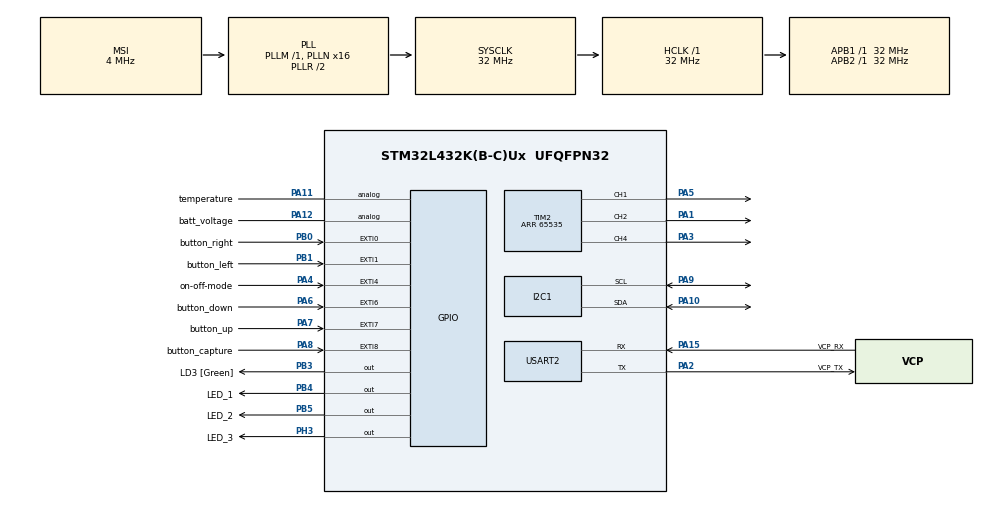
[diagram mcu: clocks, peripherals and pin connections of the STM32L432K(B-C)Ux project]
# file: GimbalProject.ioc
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FREERTOS.BinarySemaphores01=spatialSmphr,Dynamic,NULL;targetSmphr,Dynamic,NULL
FREERTOS.Tasks01=controlSysTask,8,128,StartCtrlSysTask,Default,NULL,Static,controlSysTaskBuffer,controlSysTaskControlBlock;ledBattTask,9,128,StartLedBattTask,Default,NULL,Static,ledBattTaskBuffer,ledBattTaskControlBlock;imuTask,10,128,StartIMUTask,Default,NULL,Static,imuTaskBuffer,imuTaskControlBlock;targetSetTask,12,128,StartTargetSetTask,Default,NULL,Static,targetSetTaskBuffer,targetSetTaskControlBlock;stateTask,13,128,StartStateMachine,Default,NULL,Static,stateTaskBuffer,stateTaskControlBlock;uniqueMovement,8,128,StartUniqueMovement,Default,NULL,Static,uniqueMovementBuffer,uniqueMovementControlBlock
I2C1.Timing=0x00707CBB
Mcu.Family=STM32L4
Mcu.Name=STM32L432K(B-C)Ux
Mcu.Package=UFQFPN32
NVIC.EXTI0_IRQn=true\:5\:0\:false\:false\:true\:true\:true\:true
NVIC.EXTI1_IRQn=true\:5\:0\:false\:false\:true\:true\:true\:true
NVIC.EXTI4_IRQn=true\:5\:0\:false\:false\:true\:true\:true\:true
NVIC.EXTI9_5_IRQn=true\:5\:0\:false\:false\:true\:true\:true\:true
NVIC.PriorityGroup=NVIC_PRIORITYGROUP_4
NVIC.TIM6_DAC_IRQn=true\:15\:0\:false\:false\:true\:false\:false\:true
NVIC.TimeBase=TIM6_DAC_IRQn
NVIC.TimeBaseIP=TIM6
PA0.GPIO_Label=MCO [High speed clock in]
PA0.Mode=HSE-External-Clock-Source-for-LittleOrca
PA0.Signal=RCC_CK_IN
PA1.Signal=S_TIM2_CH2
PA10.Mode=I2C
PA10.Signal=I2C1_SDA
PA11.GPIO_Label=temperature
PA11.Signal=GPIO_Analog
PA12.GPIO_Label=batt_voltage
PA12.Signal=GPIO_Analog
PA13\ (JTMS-SWDIO).GPIO_Label=SWDIO
PA13\ (JTMS-SWDIO).Mode=Serial_Wire
PA13\ (JTMS-SWDIO).Signal=SYS_JTMS-SWDIO
PA14\ (JTCK-SWCLK).GPIO_Label=SWCLK
PA14\ (JTCK-SWCLK).Mode=Serial_Wire
PA14\ (JTCK-SWCLK).Signal=SYS_JTCK-SWCLK
PA15\ (JTDI).GPIO_Label=VCP_RX
PA15\ (JTDI).Mode=Asynchronous
PA15\ (JTDI).Signal=USART2_RX
PA2.GPIO_Label=VCP_TX
PA2.Mode=Asynchronous
PA2.Signal=USART2_TX
PA3.Signal=S_TIM2_CH4
PA4.GPIO_Label=on-off-mode
PA4.GPIO_ModeDefaultEXTI=GPIO_MODE_IT_FALLING
PA4.GPIO_PuPd=GPIO_PULLUP
PA4.Signal=GPXTI4
PA5.Signal=S_TIM2_CH1
PA6.GPIO_Label=button_down
PA6.GPIO_ModeDefaultEXTI=GPIO_MODE_IT_FALLING
PA6.GPIO_PuPd=GPIO_PULLUP
PA6.Signal=GPXTI6
PA7.GPIO_Label=button_up
PA7.GPIO_ModeDefaultEXTI=GPIO_MODE_IT_FALLING
PA7.GPIO_PuPd=GPIO_PULLUP
PA7.Signal=GPXTI7
PA8.GPIO_Label=button_capture
PA8.Signal=GPXTI8
PA9.Mode=I2C
PA9.Signal=I2C1_SCL
PB0.GPIO_Label=button_right
PB0.GPIO_ModeDefaultEXTI=GPIO_MODE_IT_FALLING
PB0.GPIO_PuPd=GPIO_PULLUP
PB0.Signal=GPXTI0
PB1.GPIO_Label=button_left
PB1.GPIO_ModeDefaultEXTI=GPIO_MODE_IT_FALLING
PB1.GPIO_PuPd=GPIO_PULLUP
PB1.Signal=GPXTI1
PB3\ (JTDO-TRACESWO).GPIO_Label=LD3 [Green]
PB3\ (JTDO-TRACESWO).Signal=GPIO_Output
PB4\ (NJTRST).GPIO_Label=LED_1
PB4\ (NJTRST).Signal=GPIO_Output
PB5.GPIO_Label=LED_2
PB5.Signal=GPIO_Output
PB6.Signal=USART1_TX
PB7.Signal=USART1_RX
PC14-OSC32_IN\ (PC14).Mode=LSE-External-Oscillator
PC14-OSC32_IN\ (PC14).Signal=RCC_OSC32_IN
PC15-OSC32_OUT\ (PC15).Mode=LSE-External-Oscillator
PC15-OSC32_OUT\ (PC15).Signal=RCC_OSC32_OUT
PH3-BOOT0.GPIO_Label=LED_3
PH3-BOOT0.Signal=GPIO_Output
ProjectManager.HeapSize=0x200
ProjectManager.StackSize=0x400
ProjectManager.TargetToolchain=STM32CubeIDE
RCC.AHBFreq_Value=32000000
RCC.APB1Freq_Value=32000000
RCC.APB1TimFreq_Value=32000000
RCC.APB2Freq_Value=32000000
RCC.APB2TimFreq_Value=32000000
RCC.CortexFreq_Value=32000000
RCC.HCLKFreq_Value=32000000
RCC.HSE_VALUE=8000000
RCC.HSI16_VALUE=16000000
RCC.HSI48_VALUE=48000000
RCC.HSI_VALUE=16000000
RCC.MSI_VALUE=4000000
RCC.PLLMUL=RCC_PLLMUL_4
RCC.PLLN=16
RCC.SYSCLKFreq_VALUE=32000000
RCC.SYSCLKSource=RCC_SYSCLKSOURCE_PLLCLK
RCC.VCOOutputFreq_Value=64000000
SH.S_TIM2_CH1.0=TIM2_CH1,PWM Generation1 CH1
SH.S_TIM2_CH2.0=TIM2_CH2,PWM Generation2 CH2
SH.S_TIM2_CH4.0=TIM2_CH4,PWM Generation4 CH4
TIM2.AutoReloadPreload=TIM_AUTORELOAD_PRELOAD_ENABLE
TIM2.Channel-PWM\ Generation1\ CH1=TIM_CHANNEL_1
TIM2.Channel-PWM\ Generation2\ CH2=TIM_CHANNEL_2
TIM2.Channel-PWM\ Generation4\ CH4=TIM_CHANNEL_4
TIM2.Period=65535
USART2.VirtualMode-Asynchronous=VM_ASYNC
VP_FREERTOS_VS_CMSIS_V2.Mode=CMSIS_V2
VP_SYS_VS_tim6.Mode=TIM6
VP_TIM2_VS_ClockSourceINT.Mode=Internal
board=NUCLEO-L432KC

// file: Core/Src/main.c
/* USER CODE BEGIN Header */
/**
  ******************************************************************************
  * @file           : main.c
  * @brief          : Main program body
  ******************************************************************************
  * @attention
  *
  * <h2><center>&copy; Copyright (c) 2021 STMicroelectronics.
  * All rights reserved.</center></h2>
  *
  * This software component is licensed by ST under BSD 3-Clause license,
  * the "License"; You may not use this file except in compliance with the
  * License. You may obtain a copy of the License at:
  *                        opensource.org/licenses/BSD-3-Clause
  *
  ******************************************************************************
  */
/* USER CODE END Header */
#include "main.h"
#include "cmsis_os.h"

/* USER CODE BEGIN Includes */
#include <stdio.h>
#include "bno055_stm32.h"
/* USER CODE END Includes */

/* USER CODE BEGIN PTD */
#ifdef __GNUC__
  /* With GCC, small printf (option LD Linker->Libraries->Small printf
     set to 'Yes') calls __io_putchar() */
  #define PUTCHAR_PROTOTYPE int __io_putchar(int ch)
#else
  #define PUTCHAR_PROTOTYPE int fputc(int ch, FILE *f)
#endif /* __GNUC__ */
/* USER CODE END PTD */

I2C_HandleTypeDef hi2c1;

TIM_HandleTypeDef htim2;

UART_HandleTypeDef huart2;

/* Definitions for controlSysTask */
osThreadId_t controlSysTaskHandle;
const osThreadAttr_t controlSysTask_attributes = {
  .name = "controlSysTask",
  .stack_size = 128 * 4,
  .priority = (osPriority_t) osPriorityLow,
};
/* Definitions for ledBattTask */
osThreadId_t ledBattTaskHandle;
const osThreadAttr_t ledBattTask_attributes = {
  .name = "ledBattTask",
  .stack_size = 128 * 4,
  .priority = (osPriority_t) osPriorityLow1,
};
/* Definitions for imuTask */
osThreadId_t imuTaskHandle;
const osThreadAttr_t imuTask_attributes = {
  .name = "imuTask",
  .stack_size = 128 * 4,
  .priority = (osPriority_t) osPriorityLow2,
};
/* Definitions for spatialSmphr */
osSemaphoreId_t spatialSmphrHandle;
const osSemaphoreAttr_t spatialSmphr_attributes = {
  .name = "spatialSmphr"
};

void SystemClock_Config(void);
static void MX_GPIO_Init(void);
static void MX_USART2_UART_Init(void);
static void MX_TIM2_Init(void);
static void MX_I2C1_Init(void);
void StartCtrlSysTask(void *argument);
void StartLedBattTask(void *argument);
void StartIMUTask(void *argument);

/* USER CODE BEGIN 0 */
PUTCHAR_PROTOTYPE
{
  /* Place your implementation of fputc here */
  /* e.g. write a character to the EVAL_COM1 and Loop until the end of transmission */
  HAL_UART_Transmit(&huart2, (uint8_t *)&ch, 1, 0xFFFF);

  return ch;
}

bno055_vector_t spatialOrientation;
/* USER CODE END 0 */

int main(void)
{

  /* MCU Configuration--------------------------------------------------------*/

  /* Reset of all peripherals, Initializes the Flash interface and the Systick. */
  HAL_Init();

  /* Configure the system clock */
  SystemClock_Config();

  /* Initialize all configured peripherals */
  MX_GPIO_Init();
  MX_USART2_UART_Init();
  MX_TIM2_Init();
  MX_I2C1_Init();

  /* Init scheduler */
  osKernelInitialize();

  /* Create the semaphores(s) */
  /* creation of spatialSmphr */
  spatialSmphrHandle = osSemaphoreNew(1, 1, &spatialSmphr_attributes);

  /* Create the thread(s) */
  /* creation of controlSysTask */
  controlSysTaskHandle = osThreadNew(StartCtrlSysTask, NULL, &controlSysTask_attributes);

  /* creation of ledBattTask */
  ledBattTaskHandle = osThreadNew(StartLedBattTask, NULL, &ledBattTask_attributes);

  /* creation of imuTask */
  imuTaskHandle = osThreadNew(StartIMUTask, NULL, &imuTask_attributes);

  /* Start scheduler */
  osKernelStart();

  /* We should never get here as control is now taken by the scheduler */
  /* Infinite loop */
  while (1)
  {

  }
}

void SystemClock_Config(void)
{
  RCC_OscInitTypeDef RCC_OscInitStruct = {0};
  RCC_ClkInitTypeDef RCC_ClkInitStruct = {0};

  /** Configure the main internal regulator output voltage
  */
  if (HAL_PWREx_ControlVoltageScaling(PWR_REGULATOR_VOLTAGE_SCALE1) != HAL_OK)
  {
    Error_Handler();
  }
  /** Configure LSE Drive Capability
  */
  HAL_PWR_EnableBkUpAccess();
  __HAL_RCC_LSEDRIVE_CONFIG(RCC_LSEDRIVE_LOW);
  /** Initializes the RCC Oscillators according to the specified parameters
  * in the RCC_OscInitTypeDef structure.
  */
  RCC_OscInitStruct.OscillatorType = RCC_OSCILLATORTYPE_LSE|RCC_OSCILLATORTYPE_MSI;
  RCC_OscInitStruct.LSEState = RCC_LSE_ON;
  RCC_OscInitStruct.MSIState = RCC_MSI_ON;
  RCC_OscInitStruct.MSICalibrationValue = 0;
  RCC_OscInitStruct.MSIClockRange = RCC_MSIRANGE_6;
  RCC_OscInitStruct.PLL.PLLState = RCC_PLL_ON;
  RCC_OscInitStruct.PLL.PLLSource = RCC_PLLSOURCE_MSI;
  RCC_OscInitStruct.PLL.PLLM = 1;
  RCC_OscInitStruct.PLL.PLLN = 16;
  RCC_OscInitStruct.PLL.PLLP = RCC_PLLP_DIV7;
  RCC_OscInitStruct.PLL.PLLQ = RCC_PLLQ_DIV2;
  RCC_OscInitStruct.PLL.PLLR = RCC_PLLR_DIV2;
  if (HAL_RCC_OscConfig(&RCC_OscInitStruct) != HAL_OK)
  {
    Error_Handler();
  }
  /** Initializes the CPU, AHB and APB buses clocks
  */
  RCC_ClkInitStruct.ClockType = RCC_CLOCKTYPE_HCLK|RCC_CLOCKTYPE_SYSCLK
                              |RCC_CLOCKTYPE_PCLK1|RCC_CLOCKTYPE_PCLK2;
  RCC_ClkInitStruct.SYSCLKSource = RCC_SYSCLKSOURCE_PLLCLK;
  RCC_ClkInitStruct.AHBCLKDivider = RCC_SYSCLK_DIV1;
  RCC_ClkInitStruct.APB1CLKDivider = RCC_HCLK_DIV1;
  RCC_ClkInitStruct.APB2CLKDivider = RCC_HCLK_DIV1;

  if (HAL_RCC_ClockConfig(&RCC_ClkInitStruct, FLASH_LATENCY_1) != HAL_OK)
  {
    Error_Handler();
  }
  /** Enable MSI Auto calibration
  */
  HAL_RCCEx_EnableMSIPLLMode();
}

static void MX_I2C1_Init(void)
{

  hi2c1.Instance = I2C1;
  hi2c1.Init.Timing = 0x00707CBB;
  hi2c1.Init.OwnAddress1 = 0;
  hi2c1.Init.AddressingMode = I2C_ADDRESSINGMODE_7BIT;
  hi2c1.Init.DualAddressMode = I2C_DUALADDRESS_DISABLE;
  hi2c1.Init.OwnAddress2 = 0;
  hi2c1.Init.OwnAddress2Masks = I2C_OA2_NOMASK;
  hi2c1.Init.GeneralCallMode = I2C_GENERALCALL_DISABLE;
  hi2c1.Init.NoStretchMode = I2C_NOSTRETCH_DISABLE;
  if (HAL_I2C_Init(&hi2c1) != HAL_OK)
  {
    Error_Handler();
  }
  /** Configure Analogue filter
  */
  if (HAL_I2CEx_ConfigAnalogFilter(&hi2c1, I2C_ANALOGFILTER_ENABLE) != HAL_OK)
  {
    Error_Handler();
  }
  /** Configure Digital filter
  */
  if (HAL_I2CEx_ConfigDigitalFilter(&hi2c1, 0) != HAL_OK)
  {
    Error_Handler();
  }

}

static void MX_TIM2_Init(void)
{

  TIM_ClockConfigTypeDef sClockSourceConfig = {0};
  TIM_MasterConfigTypeDef sMasterConfig = {0};
  TIM_OC_InitTypeDef sConfigOC = {0};

  htim2.Instance = TIM2;
  htim2.Init.Prescaler = 0;
  htim2.Init.CounterMode = TIM_COUNTERMODE_UP;
  htim2.Init.Period = 65535;
  htim2.Init.ClockDivision = TIM_CLOCKDIVISION_DIV1;
  htim2.Init.AutoReloadPreload = TIM_AUTORELOAD_PRELOAD_ENABLE;
  if (HAL_TIM_Base_Init(&htim2) != HAL_OK)
  {
    Error_Handler();
  }
  sClockSourceConfig.ClockSource = TIM_CLOCKSOURCE_INTERNAL;
  if (HAL_TIM_ConfigClockSource(&htim2, &sClockSourceConfig) != HAL_OK)
  {
    Error_Handler();
  }
  if (HAL_TIM_PWM_Init(&htim2) != HAL_OK)
  {
    Error_Handler();
  }
  sMasterConfig.MasterOutputTrigger = TIM_TRGO_RESET;
  sMasterConfig.MasterSlaveMode = TIM_MASTERSLAVEMODE_DISABLE;
  if (HAL_TIMEx_MasterConfigSynchronization(&htim2, &sMasterConfig) != HAL_OK)
  {
    Error_Handler();
  }
  sConfigOC.OCMode = TIM_OCMODE_PWM1;
  sConfigOC.Pulse = 0;
  sConfigOC.OCPolarity = TIM_OCPOLARITY_HIGH;
  sConfigOC.OCFastMode = TIM_OCFAST_DISABLE;
  if (HAL_TIM_PWM_ConfigChannel(&htim2, &sConfigOC, TIM_CHANNEL_1) != HAL_OK)
  {
    Error_Handler();
  }
  if (HAL_TIM_PWM_ConfigChannel(&htim2, &sConfigOC, TIM_CHANNEL_2) != HAL_OK)
  {
    Error_Handler();
  }
  if (HAL_TIM_PWM_ConfigChannel(&htim2, &sConfigOC, TIM_CHANNEL_4) != HAL_OK)
  {
    Error_Handler();
  }
  HAL_TIM_MspPostInit(&htim2);

}

static void MX_USART2_UART_Init(void)
{

  huart2.Instance = USART2;
  huart2.Init.BaudRate = 115200;
  huart2.Init.WordLength = UART_WORDLENGTH_8B;
  huart2.Init.StopBits = UART_STOPBITS_1;
  huart2.Init.Parity = UART_PARITY_NONE;
  huart2.Init.Mode = UART_MODE_TX_RX;
  huart2.Init.HwFlowCtl = UART_HWCONTROL_NONE;
  huart2.Init.OverSampling = UART_OVERSAMPLING_16;
  huart2.Init.OneBitSampling = UART_ONE_BIT_SAMPLE_DISABLE;
  huart2.AdvancedInit.AdvFeatureInit = UART_ADVFEATURE_NO_INIT;
  if (HAL_UART_Init(&huart2) != HAL_OK)
  {
    Error_Handler();
  }

}

static void MX_GPIO_Init(void)
{
  GPIO_InitTypeDef GPIO_InitStruct = {0};

  /* GPIO Ports Clock Enable */
  __HAL_RCC_GPIOC_CLK_ENABLE();
  __HAL_RCC_GPIOA_CLK_ENABLE();
  __HAL_RCC_GPIOB_CLK_ENABLE();
  __HAL_RCC_GPIOH_CLK_ENABLE();

  /*Configure GPIO pin Output Level */
  HAL_GPIO_WritePin(GPIOB, LD3_Pin|LED_1_Pin|LED_2_Pin, GPIO_PIN_RESET);

  /*Configure GPIO pin Output Level */
  HAL_GPIO_WritePin(LED_3_GPIO_Port, LED_3_Pin, GPIO_PIN_RESET);

  /*Configure GPIO pins : button_on_off_mode_Pin button_down_Pin button_up_Pin button_capture_Pin */
  GPIO_InitStruct.Pin = button_on_off_mode_Pin|button_down_Pin|button_up_Pin|button_capture_Pin;
  GPIO_InitStruct.Mode = GPIO_MODE_INPUT;
  GPIO_InitStruct.Pull = GPIO_NOPULL;
  HAL_GPIO_Init(GPIOA, &GPIO_InitStruct);

  /*Configure GPIO pins : button_right_Pin button_left_Pin */
  GPIO_InitStruct.Pin = button_right_Pin|button_left_Pin;
  GPIO_InitStruct.Mode = GPIO_MODE_INPUT;
  GPIO_InitStruct.Pull = GPIO_NOPULL;
  HAL_GPIO_Init(GPIOB, &GPIO_InitStruct);

  /*Configure GPIO pins : temperature_Pin batt_voltage_Pin */
  GPIO_InitStruct.Pin = temperature_Pin|batt_voltage_Pin;
  GPIO_InitStruct.Mode = GPIO_MODE_ANALOG;
  GPIO_InitStruct.Pull = GPIO_NOPULL;
  HAL_GPIO_Init(GPIOA, &GPIO_InitStruct);

  /*Configure GPIO pins : LD3_Pin LED_1_Pin LED_2_Pin */
  GPIO_InitStruct.Pin = LD3_Pin|LED_1_Pin|LED_2_Pin;
  GPIO_InitStruct.Mode = GPIO_MODE_OUTPUT_PP;
  GPIO_InitStruct.Pull = GPIO_NOPULL;
  GPIO_InitStruct.Speed = GPIO_SPEED_FREQ_LOW;
  HAL_GPIO_Init(GPIOB, &GPIO_InitStruct);

  /*Configure GPIO pins : PB6 PB7 */
  GPIO_InitStruct.Pin = GPIO_PIN_6|GPIO_PIN_7;
  GPIO_InitStruct.Mode = GPIO_MODE_AF_PP;
  GPIO_InitStruct.Pull = GPIO_NOPULL;
  GPIO_InitStruct.Speed = GPIO_SPEED_FREQ_VERY_HIGH;
  GPIO_InitStruct.Alternate = GPIO_AF7_USART1;
  HAL_GPIO_Init(GPIOB, &GPIO_InitStruct);

  /*Configure GPIO pin : LED_3_Pin */
  GPIO_InitStruct.Pin = LED_3_Pin;
  GPIO_InitStruct.Mode = GPIO_MODE_OUTPUT_PP;
  GPIO_InitStruct.Pull = GPIO_NOPULL;
  GPIO_InitStruct.Speed = GPIO_SPEED_FREQ_LOW;
  HAL_GPIO_Init(LED_3_GPIO_Port, &GPIO_InitStruct);

}

void StartCtrlSysTask(void *argument)
{
  /* USER CODE BEGIN 5 */
	float pitch;
	int32_t pwmControl;
	HAL_TIM_PWM_Start(&htim2, TIM_CHANNEL_1);
  /* Infinite loop */
  for(;;)
  {
	osSemaphoreAcquire( spatialSmphrHandle, osWaitForever );
	pitch = spatialOrientation.y;

	if ( pitch < 0 ){
		pitch =  (-1)*pitch;
	}
	if (pitch > 60){
		pitch = 60;
	}

	pwmControl = pitch*65534/60;
	TIM2->CCR1 = pwmControl;
	osSemaphoreRelease( spatialSmphrHandle );
	osDelay(10);
  }
  osThreadTerminate(NULL);
  /* USER CODE END 5 */
}

void StartLedBattTask(void *argument)
{
  /* USER CODE BEGIN StartLedBattTask */
  /* Infinite loop */
  for(;;)
  {
	HAL_GPIO_TogglePin(GPIOB, GPIO_PIN_3);
    osDelay(800);
  }
  osThreadTerminate(NULL);
  /* USER CODE END StartLedBattTask */
}

void StartIMUTask(void *argument)
{
  /* USER CODE BEGIN StartIMUTask */
  /* Infinite loop */
	bno055_assignI2C(&hi2c1);
	bno055_setup();
	bno055_setOperationModeNDOF();
  for(;;)
  {
	osSemaphoreAcquire( spatialSmphrHandle, osWaitForever );
	spatialOrientation = bno055_getVectorEuler();
	//printf("y%.2fyp%.2fpr%.2fr\n", spatialOrientation.x, spatialOrientation.y, spatialOrientation.z);
	osSemaphoreRelease( spatialSmphrHandle );
	osDelay(30);
  }
  osThreadTerminate(NULL);
  /* USER CODE END StartIMUTask */
}

void HAL_TIM_PeriodElapsedCallback(TIM_HandleTypeDef *htim)
{
  if (htim->Instance == TIM6) {
    HAL_IncTick();
  }
}

void Error_Handler(void)
{
  __disable_irq();
  while (1)
  {
  }
}
